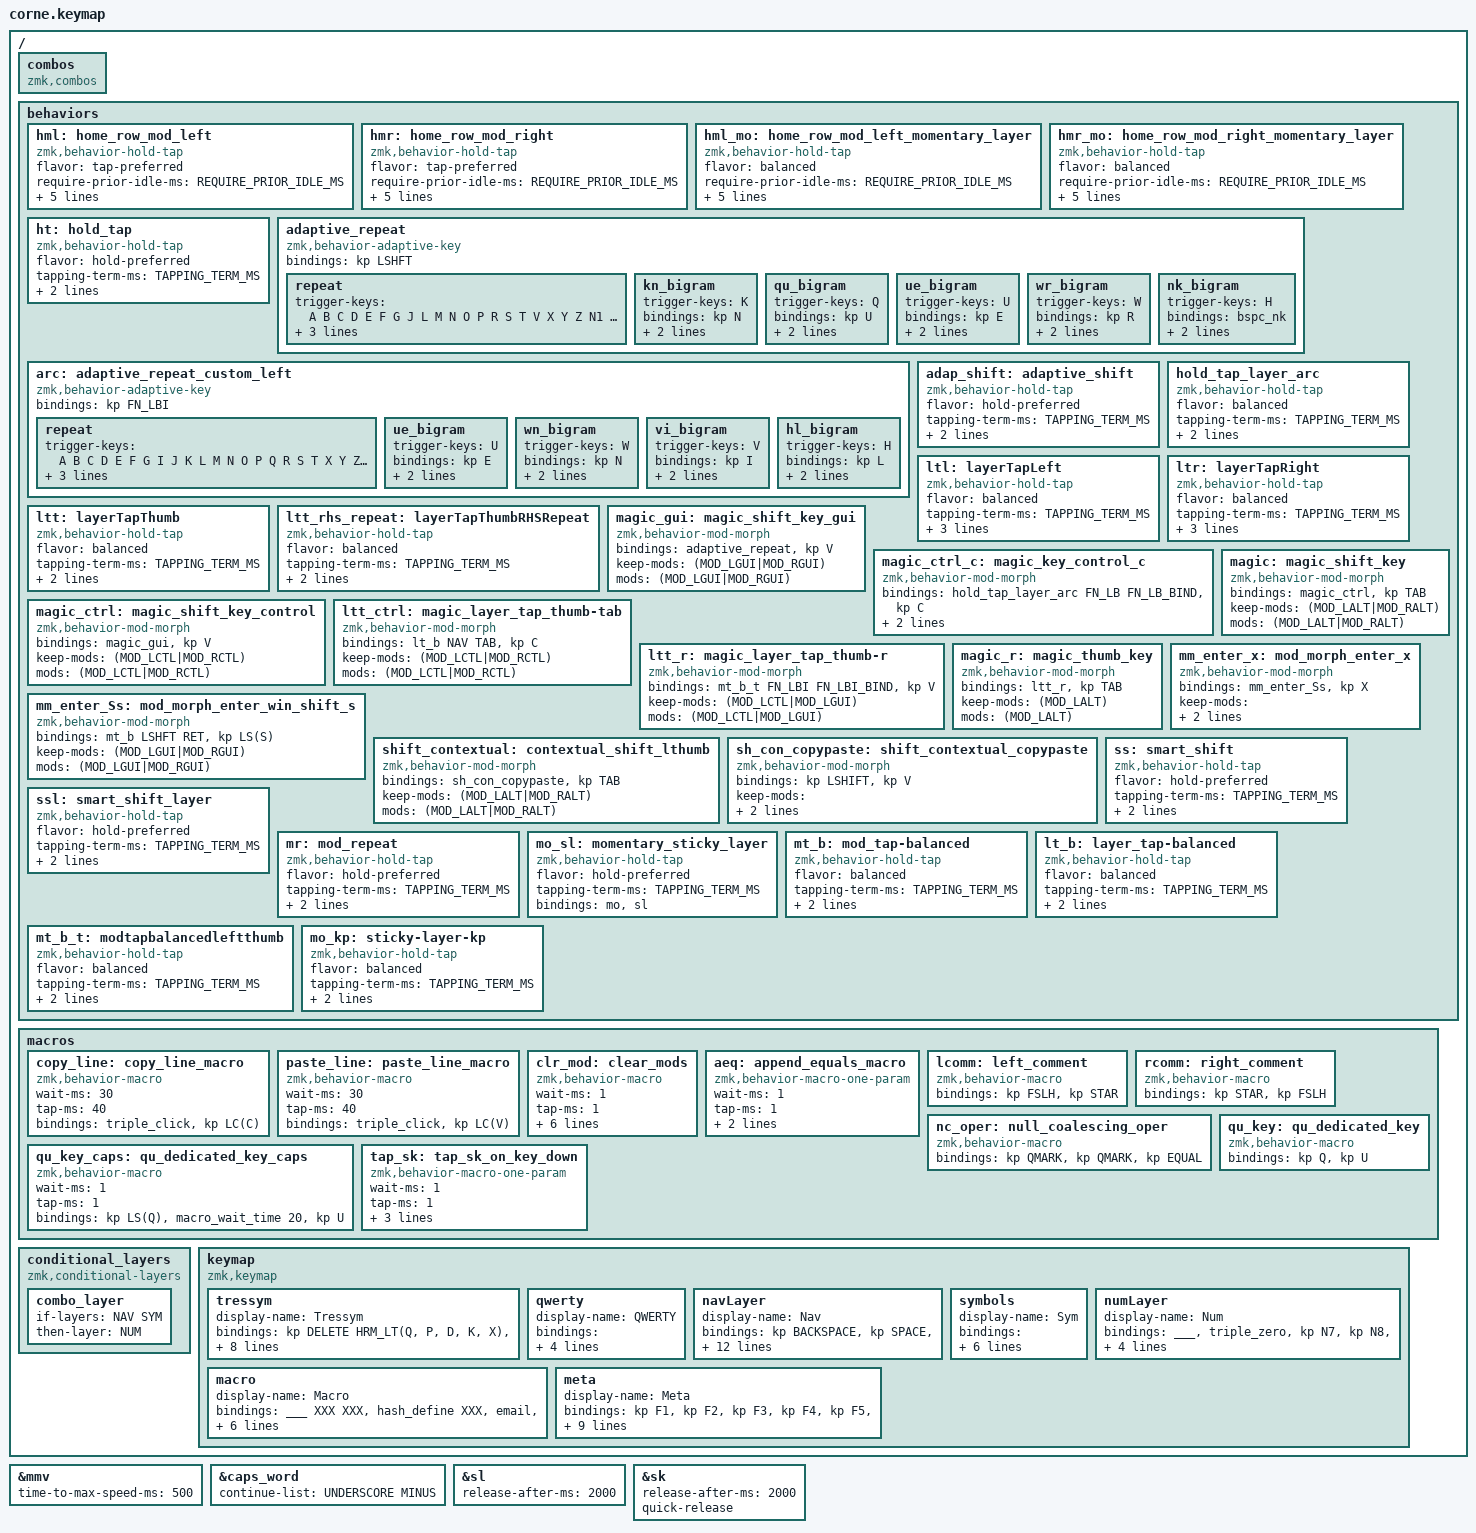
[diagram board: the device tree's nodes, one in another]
/*
 * Copyright (c) 2020 The ZMK Contributors
 *
 * SPDX-License-Identifier: MIT
 */

#include <behaviors.dtsi>
#include <dt-bindings/zmk/bt.h>

// Mouse keys
#define ZMK_POINTING_DEFAULT_MOVE_VAL 1000  // default: 600
#define ZMK_POINTING_DEFAULT_SCRL_VAL 25    // default: 10
#include <dt-bindings/zmk/pointing.h>

#define XXX &none
#define ___ &trans

// Layers
#define BASE \
0
#define QWER \
1
/*
These were in the wrong order before they were removed.
#define COLEMAK \
2
#define ENTH \
3
*/
#define NAV \
2
#define SYM \
3
#define NUM \
4
#define MACR \
5
#define META \
6


/*                                      42 KEY MATRIX / LAYOUT MAPPING

  ╭────────────────────────┬────────────────────────╮ ╭─────────────────────────┬─────────────────────────╮
  │  0   1   2   3   4   5 │  6   7   8   9  10  11 │ │ LT5 LT4 LT3 LT2 LT1 LT0 │ RT0 RT1 RT2 RT3 RT4 RT5 │
  │ 12  13  14  15  16  17 │ 18  19  20  21  22  23 │ │ LM5 LM4 LM3 LM2 LM1 LM0 │ RM0 RM1 RM2 RM3 RM4 RM5 │
  │ 24  25  26  27  28  29 │ 30  31  32  33  34  35 │ │ LB5 LB4 LB3 LB2 LB1 LB0 │ RB0 RB1 RB2 RB3 RB4 RB5 │
  ╰───────────╮ 36  37  38 │ 39  40  41 ╭───────────╯ ╰───────────╮ LH2 LH1 LH0 │ RH0 RH1 RH2 ╭───────────╯
			  ╰────────────┴────────────╯                         ╰─────────────┴─────────────╯             */

// Source key-labels.
#include <dt-bindings/zmk/keys.h>
#include "zmk-helpers/key-labels/42.h"
#define KEYS_L LT5 LT4 LT3 LT2 LT1 LT0 LM5 LM4 LM3 LM2 LM1 LM0 LB5 LB4 LB3 LB2 LB1 LB0
#define KEYS_R RT0 RT1 RT2 RT3 RT4 RT5 RM0 RM1 RM2 RM3 RM4 RM5 RB0 RB1 RB2 RB3 RB4 RB5
#define THUMBS LH2 LH1 LH0 RH0 RH1 RH2
#define THUMBS_L LH2 LH1 LH0
#define THUMBS_R RH0 RH1 RH2

// Define columns
// Left
#define LC5 LT5 LM5 LB5
#define LC4 LT4 LM4 LB4
#define LC3 LT3 LM3 LB3
#define LC2 LT2 LM2 LB2
#define LC1 LT1 LM1 LB1
#define LC0 LT0 LM0 LB0
// Right
#define RC5 RT5 RM5 RB5
#define RC4 RT4 RM4 RB4
#define RC3 RT3 RM3 RB3
#define RC2 RT2 RM2 RB2
#define RC1 RT1 RM1 RB1
#define RC0 RT0 RM0 RB0

// Define rows
// Top
#define LRT LT5 LT4 LT3 LT2 LT1 LT0
#define RRT RT0 RT1 RT2 RT3 RT4 RT5
// Middle
#define LRM LM5 LM4 LM3 LM2 LM1 LM0
#define RRM RM0 RM1 RM2 RM3 RM4 RM5
// Bottom
#define LRB LB5 LB4 LB3 LB2 LB1 LB0
#define RRB RB0 RB1 RB2 RB3 RB4 RB5


// Define HRM order

// Symbols layer is bound to middle finger because that allows you to hit }; with the current position of ; on the symbols layer.

/*
╭─────────────────────────────────────────────────┬─────────────────────────────────────────────────╮
│ HRM_LT5 HRM_LT4 HRM_LT3 HRM_LT2 HRM_LT1 HRM_LT0 │ HRM_RT0 HRM_RT1 HRM_RT2 HRM_RT3 HRM_RT4 HRM_RT5 │
│ HRM_LM5 HRM_LM4 HRM_LM3 HRM_LM2 HRM_LM1 HRM_LM0 │ HRM_RM0 HRM_RM1 HRM_RM2 HRM_RM3 HRM_RM4 HRM_RM5 │
│ HRM_LB5 HRM_LB4 HRM_LB3 HRM_LB2 HRM_LB1 HRM_LB0 │ HRM_RB0 HRM_RB1 HRM_RB2 HRM_RB3 HRM_RB4 HRM_RB5 │
╰───────────────────────╮ HRM_LH2 HRM_LH1 HRM_LH0 │ HRM_RH0 HRM_RH1 HRM_RH2 ╭───────────────────────╯
						╰─────────────────────────┴─────────────────────────╯
*/

// Top
// Left
#define HRM_LT5 XXX
#define HRM_LT4 XXX
#define HRM_LT3 XXX
#define HRM_LT2 XXX
#define HRM_LT1 XXX
#define HRM_LT0 XXX
// Right
#define HRM_RT0 XXX
#define HRM_RT1 XXX
#define HRM_RT2 XXX
#define HRM_RT3 XXX
#define HRM_RT4 XXX
#define HRM_RT5 XXX
// Middle
// Left
#define HRM_LM5 XXX
#define HRM_LM4 LGUI
#define HRM_LM3 LALT
//#define HRM_LM2 SYM
#define HRM_LM2 LSHFT
#define HRM_LM1 LCTRL
#define HRM_LM0 LSHFT
// Right
#define HRM_RM0 RSHFT
#define HRM_RM1 RCTRL
//#define HRM_RM2 SYM
#define HRM_RM2 RSHFT
#define HRM_RM3 RALT
#define HRM_RM4 RGUI
#define HRM_RM5 XXX
// Bottom
// Left
#define HRM_LB5 XXX
#define HRM_LB4 XXX
#define HRM_LB3 XXX
#define HRM_LB2 XXX
#define HRM_LB1 XXX
#define HRM_LB0 XXX
// Right
#define HRM_RB0 XXX
#define HRM_RB1 XXX
#define HRM_RB2 XXX
#define HRM_RB3 XXX
#define HRM_RB4 XXX
#define HRM_RB5 XXX


// Top row
// Left
#define HRM_LT(_one_, _two_, _three_, _four_, _five_)	\
	&kp	_one_					\
	&kp	_two_					\
	&kp _three_					\
	&kp	_four_					\
	&kp	_five_
// Right
#define HRM_RT(_one_, _two_, _three_, _four_, _five_)	\
	&kp	_one_					\
	&kp	_two_					\
	&kp _three_					\
	&kp	_four_					\
	&kp	_five_

// Middle row
// Left
#define HRM_LM(_one_, _two_, _three_, _four_, _five_)	\
	&hml	HRM_LM4 _one_		\
	&hml	HRM_LM3 _two_		\
	&hml	HRM_LM2 _three_		\
	&hml	HRM_LM1 _four_		\
	&hml	HRM_LM0 _five_
// Right
#define HRM_RM(_one_, _two_, _three_, _four_, _five_)	\
	&hmr	HRM_RM0 _one_		\
	&hmr	HRM_RM1 _two_		\
	&hmr	HRM_RM2 _three_		\
	&hmr	HRM_RM3 _four_		\
	&hmr	HRM_RM4 _five_

// Bottom row
// Left
#define HRM_LB(_one_, _two_, _three_, _four_, _five_)	\
	&kp	_one_					\
	&kp	_two_					\
	&kp _three_					\
	&kp _four_					\
	&kp	_five_
// Right
#define HRM_RB(_one_, _two_, _three_, _four_, _five_)	\
	&kp	_one_					\
	&kp _two_					\
	&kp _three_					\
	&kp	_four_					\
	&kp	_five_


// Num left | macr right : So that I can hold shift on macros.
// Positional FN defines.
//╭───────────────┬───────────────┬───────────────┬───────────────┬───────────────┬───────────────╮   ╭───────────────┬───────────────┬───────────────┬───────────────┬───────────────┬───────────────╮
//	___				___				___				___				___				___					___				___				___				___				___				___
//├───────────────┼───────────────┼───────────────┼───────────────┼───────────────┼───────────────┤   ├───────────────┼───────────────┼───────────────┼───────────────┼───────────────┼───────────────┤
	#define FN_LT MACR
																																													#define FN_RT MACR
//├───────────────┼───────────────┼───────────────┼───────────────┼───────────────┼───────────────┤   ├───────────────┼───────────────┼───────────────┼───────────────┼───────────────┼───────────────┤
//	___				___				___				___				___				___					___				___				___				___				___				___
//╰───────────────┴───────────────┴───────────────┼───────────────┼───────────────┼───────────────┤   ├───────────────┼───────────────┼───────────────┼───────────────┴───────────────┴───────────────╯
																#define FN_LB NAV
																#define FN_LB_BIND 0
																				#define FN_LBI LSHIFT
																				#define FN_LBI_BIND R
																									#define FN_RBI RSHIFT
																									#define FN_RBI_BIND SPACE
																													#define FN_RB SYM
																													#define FN_RB_BIND SQT
//                                                ╰───────────────┴───────────────┴───────────────╯   ╰───────────────┴───────────────┴───────────────╯


/*                                      42 KEY MATRIX / LAYOUT MAPPING

  ╭────────────────────────┬────────────────────────╮ ╭─────────────────────────┬─────────────────────────╮
  │  0   1   2   3   4   5 │  6   7   8   9  10  11 │ │ LT5 LT4 LT3 LT2 LT1 LT0 │ RT0 RT1 RT2 RT3 RT4 RT5 │
  │ 12  13  14  15  16  17 │ 18  19  20  21  22  23 │ │ LM5 LM4 LM3 LM2 LM1 LM0 │ RM0 RM1 RM2 RM3 RM4 RM5 │
  │ 24  25  26  27  28  29 │ 30  31  32  33  34  35 │ │ LB5 LB4 LB3 LB2 LB1 LB0 │ RB0 RB1 RB2 RB3 RB4 RB5 │
  ╰───────────╮ 36  37  38 │ 39  40  41 ╭───────────╯ ╰───────────╮ LH2 LH1 LH0 │ RH0 RH1 RH2 ╭───────────╯
			  ╰────────────┴────────────╯                         ╰─────────────┴─────────────╯             */

// Combos
/ {
	combos {
		compatible = "zmk,combos";
		// Q macro, Q is Qu instead.
		//combo_q { timeout-ms = <50>; key-positions = <LT4 LT3>; bindings = <&kp Q>; };
		// Bootloader access.
		//combo_rst_l { timeout-ms = <50>; key-positions = <LT0 LM5 LH1>; bindings = <&bootloader>; };
		//combo_rst_r { timeout-ms = <50>; key-positions = <RT0 RM5 RH1>; bindings = <&bootloader>; };

		// ( / )
		//combo_l_paren { timeout-ms = <50>; key-positions = <LT3 LT2 LM1>; bindings = <&kp LS(N9)>; };
		//combo_r_paren { timeout-ms = <50>; key-positions = <LM3 LT2 LT1>; bindings = <&kp LS(N0)>; };
		// { / }
		//combo_l_brace { timeout-ms = <50>; key-positions = <RT1 RT2 RM3>; bindings = <&kp LBRC>; };
		//combo_r_brace { timeout-ms = <50>; key-positions = <RM1 RT2 RT3>; bindings = <&kp RBRC>; };
		// [ / ]
		//combo_l_bracket { timeout-ms = <50>; key-positions = <LB3 LB2 >; bindings = <&kp LBKT>; };
		//combo_r_bracket { timeout-ms = <50>; key-positions = <LB2 LB1>; bindings = <&kp RBKT>; };
		// < / >
		//combo_l_abk { timeout-ms = <50>; key-positions = <RB2 RB1>; bindings = <&kp LT>; };
		//combo_r_abk { timeout-ms = <50>; key-positions = <RB3 RB2>; bindings = <&kp GT>; };
		// Both thumbs produces shift.
		//combo_shift_thumbs { timeout-ms = <50>; key-positions = <LH0 RH0>; bindings = <&kp LSHFT>; };
	};
};


/* Homerow mods */
#include "zmk-helpers/helper.h"

#define QUICK_TAP_MS 150
#define TAPPING_TERM_MS 160

// Generic <unshifted>, <shifted>
#define MOD_MORPH_GENERIC(_name_, _unshifted_, _shifted_)	\
_name_: _name_##mod_morph_generic_shift {					\
	compatible = "zmk,behavior-mod-morph";					\
	#binding-cells = <0>;									\
	bindings = <_unshifted_>, <_shifted_>;					\
	mods = <(MOD_LSFT|MOD_RSFT)>;							\
};
// Generic HML macros
#define HML_GENERIC(_name_, _binding_)						\
hml_##_name_: home_row_mod_left_##_name_ {					\
	compatible = "zmk,behavior-hold-tap";					\
	#binding-cells = <2>;									\
	flavor = "balanced";									\
	require-prior-idle-ms = <150>;							\
	tapping-term-ms = <TAPPING_TERM_MS>;					\
	quick-tap-ms = <QUICK_TAP_MS>;							\
	bindings = <&kp>, <_binding_>;							\
	hold-trigger-key-positions = <KEYS_R THUMBS>; /* RHS */	\
	hold-trigger-on-release;								\
};
#define HMR_GENERIC(_name_, _binding_)	\
hmr_##_name_: home_row_mod_right_##_name_ {					\
	compatible = "zmk,behavior-hold-tap";					\
	#binding-cells = <2>;									\
	flavor = "balanced";									\
	require-prior-idle-ms = <150>;							\
	tapping-term-ms = <TAPPING_TERM_MS>;					\
	quick-tap-ms = <QUICK_TAP_MS>;							\
	bindings = <&kp>, <_binding_>;							\
	hold-trigger-key-positions = <KEYS_L THUMBS>; /* LHS */	\
	hold-trigger-on-release;								\
};


// ARC Idle ms
#define MAX_PRIOR_IDLE_MS 350
#define ARC_MAX_PRIOR_IDLE_MS 1000

// HRM Idle ms
#define REQUIRE_PRIOR_IDLE_MS 200

// Non-macro setup
/ {
	behaviors {
		// Home row mods
		hml: home_row_mod_left {
			compatible = "zmk,behavior-hold-tap";
			#binding-cells = <2>;
			flavor = "tap-preferred";
			require-prior-idle-ms = <REQUIRE_PRIOR_IDLE_MS>;
			tapping-term-ms = <TAPPING_TERM_MS>;
			quick-tap-ms = <QUICK_TAP_MS>;
			bindings = <&kp>, <&kp>;
			// List of keys on the right side of the keyboard
			hold-trigger-key-positions = <KEYS_R THUMBS>;
			hold-trigger-on-release;
		};
		hmr: home_row_mod_right {
			compatible = "zmk,behavior-hold-tap";
			#binding-cells = <2>;
			flavor = "tap-preferred";
			require-prior-idle-ms = <REQUIRE_PRIOR_IDLE_MS>;
			tapping-term-ms = <TAPPING_TERM_MS>;
			quick-tap-ms = <QUICK_TAP_MS>;
			bindings = <&kp>, <&kp>;
			// List of keys on the left side of the keyboard
			hold-trigger-key-positions = <KEYS_L THUMBS>;
			hold-trigger-on-release;
		};
		// Home row momentary layer keys
		hml_mo: home_row_mod_left_momentary_layer {
			compatible = "zmk,behavior-hold-tap";
			#binding-cells = <2>;
			flavor = "balanced";
			require-prior-idle-ms = <REQUIRE_PRIOR_IDLE_MS>;
			tapping-term-ms = <TAPPING_TERM_MS>;
			quick-tap-ms = <QUICK_TAP_MS>;
			bindings = <&mo>, <&kp>;
			// List of keys on the right side of the keyboard
			hold-trigger-key-positions = <KEYS_R THUMBS>;
			hold-trigger-on-release;
		};
		hmr_mo: home_row_mod_right_momentary_layer {
			compatible = "zmk,behavior-hold-tap";
			#binding-cells = <2>;
			flavor = "balanced";
			require-prior-idle-ms = <REQUIRE_PRIOR_IDLE_MS>;
			tapping-term-ms = <TAPPING_TERM_MS>;
			quick-tap-ms = <QUICK_TAP_MS>;
			bindings = <&mo>, <&kp>;
			// List of keys on the left side of the keyboard
			hold-trigger-key-positions = <KEYS_L THUMBS>;
			hold-trigger-on-release;
		};

		// Hold tap
		ht: hold_tap {
			compatible = "zmk,behavior-hold-tap";
			#binding-cells = <2>;
			flavor = "hold-preferred";
			//require-prior-idle-ms = <150>;
			tapping-term-ms = <TAPPING_TERM_MS>;
			quick-tap-ms = <QUICK_TAP_MS>;
			bindings = <&kp>, <&kp>;
			// List of keys on the left side of the keyboard
			//hold-trigger-key-positions = <RC5 KEYS_L THUMBS>;
			//hold-trigger-on-release;
		};

		// Magic shift / adaptive key
		adaptive_repeat: adaptive_repeat {
			compatible = "zmk,behavior-adaptive-key";
			#binding-cells = <0>;
			//bindings = <&adap_shift LSHFT TAB>;
			//bindings = <___>;
			bindings = <&kp LSHFT>;
			repeat {
				trigger-keys = <
					A B C D E F G J L M N O P R S T V X Y Z
					N1 N2 N3 N4 N5 N6 N7 N8 N9 N0
					TAB
					EXCL MINUS BSLH AT HASH PRCNT PLUS EQUAL GRAVE
					LT LBKT LBRC RS(N9) SPACE DOLLAR LS(N0) RBRC RBKT GT
					DQT COMMA TILDE CARET FSLH SEMI COLON STAR PIPE AMPS DOT SQT
				>;
				bindings = <&key_repeat>;
				max-prior-idle-ms = <MAX_PRIOR_IDLE_MS>;
				strict-modifiers;
			};
			// Single finger bigram prevention.
			kn_bigram {
				trigger-keys = <K>;
				bindings = <&kp N>;
				max-prior-idle-ms = <MAX_PRIOR_IDLE_MS>;
				strict-modifiers;
			};
			/* This one was too annoying.
			nk_bigram {
				trigger-keys = <N>;
				bindings = <&kp K>;
				max-prior-idle-ms = <MAX_PRIOR_IDLE_MS>;
				strict-modifiers;
			};
			*/
			qu_bigram {
				trigger-keys = <Q>;
				bindings = <&kp U>;
				max-prior-idle-ms = <MAX_PRIOR_IDLE_MS>;
				strict-modifiers;
			};
			ue_bigram {
				trigger-keys = <U>;
				bindings = <&kp E>;
				max-prior-idle-ms = <MAX_PRIOR_IDLE_MS>;
				strict-modifiers;
			};
			wr_bigram {
				trigger-keys = <W>;
				bindings = <&kp R>;
				max-prior-idle-ms = <MAX_PRIOR_IDLE_MS>;
				strict-modifiers;
			};
			// i?_bigram
			// The I bigram is disabled due to the frequency with which I use the key in VIM to start typing.
			// NK Bigram
			nk_bigram {
				trigger-keys = <H>;
				bindings = <&bspc_nk>;
				max-prior-idle-ms = <MAX_PRIOR_IDLE_MS>;
				strict-modifiers;
			};
		};

		// Magic shift / adaptive key
		arc: adaptive_repeat_custom_left {
			compatible = "zmk,behavior-adaptive-key";
			#binding-cells = <0>;
			//bindings = <&adap_shift LSHFT TAB>;
			bindings = <&kp FN_LBI>;
			repeat {
				trigger-keys = <
					A B C D E F G I J K L M N O P Q R S T X Y Z
					N1 N2 N3 N4 N5 N6 N7 N8 N9 N0
					TAB
					EXCL MINUS BSLH AT HASH PRCNT PLUS EQUAL GRAVE
					LT LBKT LBRC RS(N9) SPACE DOLLAR LS(N0) RBRC RBKT GT
					DQT COMMA TILDE CARET FSLH SEMI COLON STAR PIPE AMPS DOT SQT
				>;
				bindings = <&key_repeat>;
				max-prior-idle-ms = <ARC_MAX_PRIOR_IDLE_MS>;
				strict-modifiers;
			};
			// Single finger bigram prevention.
			ue_bigram {
				trigger-keys = <U>;
				bindings = <&kp E>;
				max-prior-idle-ms = <ARC_MAX_PRIOR_IDLE_MS>;
				strict-modifiers;
			};
			wn_bigram {
				trigger-keys = <W>;
				bindings = <&kp N>;
				max-prior-idle-ms = <ARC_MAX_PRIOR_IDLE_MS>;
				strict-modifiers;
			};
			vi_bigram {
				trigger-keys = <V>;
				bindings = <&kp I>;
				max-prior-idle-ms = <ARC_MAX_PRIOR_IDLE_MS>;
				strict-modifiers;
			};
			hl_bigram {
				trigger-keys = <H>;
				bindings = <&kp L>;
				max-prior-idle-ms = <ARC_MAX_PRIOR_IDLE_MS>;
				strict-modifiers;
			};
		};

		adap_shift: adaptive_shift {
			compatible = "zmk,behavior-hold-tap";
			#binding-cells = <2>;
			flavor = "hold-preferred";
			//require-prior-idle-ms = <150>;
			tapping-term-ms = <TAPPING_TERM_MS>;
			quick-tap-ms = <QUICK_TAP_MS>;
			bindings = <&kp>, <&kp>;
			//hold-trigger-key-positions = <RC5 KEYS_L THUMBS>; // List of keys on the left side of the keyboard
			//hold-trigger-on-release;
		};

		hold_tap_layer_arc: hold_tap_layer_arc {
			compatible = "zmk,behavior-hold-tap";
			#binding-cells = <2>;
			flavor = "balanced";
			tapping-term-ms = <TAPPING_TERM_MS>;
			quick-tap-ms = <QUICK_TAP_MS>;
			bindings = <&mo>, <&arc>;
		};

		// Left hand layer tap key
		ltl: layerTapLeft {
			compatible = "zmk,behavior-hold-tap";
			#binding-cells = <2>;
			flavor = "balanced";
			//require-prior-idle-ms = <150>;
			tapping-term-ms = <TAPPING_TERM_MS>;
			quick-tap-ms = <QUICK_TAP_MS>;
			bindings = <&mo>, <&kp>;
			hold-trigger-key-positions = <LC5 KEYS_R THUMBS>; /* RHS */
			//hold-trigger-on-release;
		};

		// Right hand layer tap key
		ltr: layerTapRight {
			compatible = "zmk,behavior-hold-tap";
			#binding-cells = <2>;
			flavor = "balanced";
			//require-prior-idle-ms = <150>;
			tapping-term-ms = <TAPPING_TERM_MS>;
			quick-tap-ms = <QUICK_TAP_MS>;
			bindings = <&mo>, <&kp>;
			hold-trigger-key-positions = <RC5 KEYS_L THUMBS>; /* LHS */
			//hold-trigger-on-release;
		};

		// Right hand layer tap key
		ltt: layerTapThumb {
			compatible = "zmk,behavior-hold-tap";
			#binding-cells = <2>;
			flavor = "balanced";
			//require-prior-idle-ms = <150>;
			tapping-term-ms = <TAPPING_TERM_MS>;
			quick-tap-ms = <QUICK_TAP_MS>;
			bindings = <&mo>, <&kp>;
			//hold-trigger-key-positions = <RC5 KEYS_L THUMBS>; /* LHS */
			//hold-trigger-on-release;
		};
		ltt_rhs_repeat: layerTapThumbRHSRepeat {
			compatible = "zmk,behavior-hold-tap";
			#binding-cells = <2>;
			flavor = "balanced";
			//require-prior-idle-ms = <150>;
			tapping-term-ms = <TAPPING_TERM_MS>;
			quick-tap-ms = <QUICK_TAP_MS>;
			bindings = <&kp>, <&adaptive_repeat>;
			//hold-trigger-key-positions = <RC5 KEYS_L THUMBS>; /* LHS */
			//hold-trigger-on-release;
		};

		/*
		HML_GENERIC(dot_cln, &dot_cln)
		HML_GENERIC(EN4, &EN4)
		HML_GENERIC(EN5, &EN5)
		HML_GENERIC(EN6, &EN6)
		*/


		// Mod morphs
		magic_gui: magic_shift_key_gui {
			compatible = "zmk,behavior-mod-morph";
			#binding-cells = <0>;
			bindings = <&adaptive_repeat>, <&kp V>;
			keep-mods = <(MOD_LGUI|MOD_RGUI)>;
			mods = <(MOD_LGUI|MOD_RGUI)>;
		};
		magic_ctrl_c: magic_key_control_c {
			compatible = "zmk,behavior-mod-morph";
			#binding-cells = <0>;
			//bindings = <&mt_b FN_LB FN_LB_BIND>, <&kp C>;
			bindings = <&hold_tap_layer_arc FN_LB FN_LB_BIND>, <&kp C>;
			keep-mods = <(MOD_LCTL|MOD_RCTL)>;
			mods = <(MOD_LCTL|MOD_RCTL)>;
		};
		magic_ctrl: magic_shift_key_control {
			compatible = "zmk,behavior-mod-morph";
			#binding-cells = <0>;
			bindings = <&magic_gui>, <&kp V>;
			keep-mods = <(MOD_LCTL|MOD_RCTL)>;
			mods = <(MOD_LCTL|MOD_RCTL)>;
		};
		magic: magic_shift_key {
			compatible = "zmk,behavior-mod-morph";
			#binding-cells = <0>;
			bindings = <&magic_ctrl>, <&kp TAB>;
			keep-mods = <(MOD_LALT|MOD_RALT)>;
			mods = <(MOD_LALT|MOD_RALT)>;
		};
		ltt_ctrl: magic_layer_tap_thumb-tab {
			compatible = "zmk,behavior-mod-morph";
			#binding-cells = <0>;
			//bindings = <&ltt FN_LB MINUS>, <&kp C>;
			// Hardcoded to avoid conflict with other layers.
			bindings = <&lt_b NAV TAB>, <&kp C>;
			keep-mods = <(MOD_LCTL|MOD_RCTL)>;
			mods = <(MOD_LCTL|MOD_RCTL)>;
		};
		ltt_r: magic_layer_tap_thumb-r {
			compatible = "zmk,behavior-mod-morph";
			#binding-cells = <0>;
			//bindings = <&ltt FN_LB MINUS>, <&kp C>;
			bindings = <&mt_b_t FN_LBI FN_LBI_BIND>, <&kp V>;
			//keep-mods = <(MOD_LCTL|MOD_RCTL|MOD_LGUI|MOD_RGUI)>;
			keep-mods = <(MOD_LCTL|MOD_LGUI)>;
			//mods = <(MOD_LCTL|MOD_RCTL|MOD_LGUI|MOD_RGUI)>;
			mods = <(MOD_LCTL|MOD_LGUI)>;
		};
		magic_r: magic_thumb_key {
			compatible = "zmk,behavior-mod-morph";
			#binding-cells = <0>;
			//bindings = <&ltt FN_LB MINUS>, <&kp C>;
			bindings = <&ltt_r>, <&kp TAB>;
			//keep-mods = <(MOD_LALT|MOD_RALT)>;
			keep-mods = <(MOD_LALT)>;
			//mods = <(MOD_LALT|MOD_RALT)>;
			mods = <(MOD_LALT)>;
		};
		mm_enter_x: mod_morph_enter_x {
			compatible = "zmk,behavior-mod-morph";
			#binding-cells = <0>;
			bindings = <&mm_enter_Ss>, <&kp X>;
			keep-mods = <(MOD_LCTL|MOD_RCTL|MOD_LGUI|MOD_RGUI)>;
			mods = <(MOD_LCTL|MOD_RCTL)>;
		};
		mm_enter_Ss: mod_morph_enter_win_shift_s {
			compatible = "zmk,behavior-mod-morph";
			#binding-cells = <0>;
			bindings = <&mt_b LSHFT RET>, <&kp LS(S)>;
			keep-mods = <(MOD_LGUI|MOD_RGUI)>;
			mods = <(MOD_LGUI|MOD_RGUI)>;
		};

		shift_contextual: contextual_shift_lthumb {
			compatible = "zmk,behavior-mod-morph";
			#binding-cells = <0>;
			bindings = <&sh_con_copypaste>, <&kp TAB>;
			keep-mods = <(MOD_LALT|MOD_RALT)>;
			mods = <(MOD_LALT|MOD_RALT)>;
		};
		sh_con_copypaste: shift_contextual_copypaste {
			compatible = "zmk,behavior-mod-morph";
			#binding-cells = <0>;
			//bindings = <&ltt FN_LB MINUS>, <&kp C>;
			bindings = <&kp LSHIFT>, <&kp V>;
			keep-mods = <(MOD_LCTL|MOD_RCTL|MOD_LGUI|MOD_RGUI)>;
			mods = <(MOD_LCTL|MOD_RCTL|MOD_LGUI|MOD_RGUI)>;
		};

		// , / ;
		MOD_MORPH_GENERIC(c_scln, &kp COMMA, &kp SEMI)
		// . / :
		MOD_MORPH_GENERIC(dot_cln, &kp DOT, &kp COLON)
		// ! / ?
		MOD_MORPH_GENERIC(bqm, &kp EXCL, &kp QMARK)
		// ? / !
		MOD_MORPH_GENERIC(qmb, &kp QMARK, &kp EXCL)
		// Space / Underscore
		MOD_MORPH_GENERIC(spund, &kp SPACE, &kp UNDER)
		// Underscore / Minus
		MOD_MORPH_GENERIC(undmin, &kp UNDER, &kp MINUS)
		// Forwardslash / Backslash
		MOD_MORPH_GENERIC(fsbs, &kp FSLH, &kp BACKSLASH)
		// qu / Qu
		MOD_MORPH_GENERIC(QU_bi, &qu_key, &qu_key_caps)

		// Explicit digit keycodes, so they can't be shifted into symbols.
		MOD_MORPH_GENERIC(EN1, &kp N1, &kp N1)
		MOD_MORPH_GENERIC(EN2, &kp N2, &kp N2)
		MOD_MORPH_GENERIC(EN3, &kp N3, &kp N3)
		MOD_MORPH_GENERIC(EN4, &kp N4, &kp N4)
		MOD_MORPH_GENERIC(EN5, &kp N5, &kp N5)
		MOD_MORPH_GENERIC(EN6, &kp N6, &kp N6)
		MOD_MORPH_GENERIC(EN7, &kp N7, &kp N7)
		MOD_MORPH_GENERIC(EN8, &kp N8, &kp N8)
		MOD_MORPH_GENERIC(EN9, &kp N9, &kp N9)
		MOD_MORPH_GENERIC(EN0, &kp N0, &kp N0)

		// Bluetooth clear hold
		//MOD_MORPH_GENERIC(btc_hold, XXX, &bt BT_CLR)

		// Numbers / F keys row
		MOD_MORPH_GENERIC(mm_transF1, &trans, &kp F1)
		//MOD_MORPH_GENERIC(mm_transF1, &kp TAB, &kp F1)
		MOD_MORPH_GENERIC(mm_N1F2,	&kp N1, &kp F2)
		MOD_MORPH_GENERIC(mm_N2F3,	&kp N2, &kp F3)
		MOD_MORPH_GENERIC(mm_N3F4,	&kp N3, &kp F4)
		MOD_MORPH_GENERIC(mm_N4F5,	&kp N4, &kp F5)
		MOD_MORPH_GENERIC(mm_N5F6,	&kp N5, &kp F6)
		MOD_MORPH_GENERIC(mm_N6F7,	&kp N6, &kp F7)
		MOD_MORPH_GENERIC(mm_N7F8,	&kp N7, &kp F8)
		MOD_MORPH_GENERIC(mm_N8F9,	&kp N8, &kp F9)
		MOD_MORPH_GENERIC(mm_N9F10,	&kp N9, &kp F10)
		MOD_MORPH_GENERIC(mm_N0F11,	&kp N0, &kp F11)
		MOD_MORPH_GENERIC(mm_transF12, &trans, &kp F12)
		//MOD_MORPH_GENERIC(mm_transF12, &kp BSPC, &kp F12)

		MOD_MORPH_GENERIC(mm_bt0, &bt BT_SEL 0, &bt BT_DISC 0)
		MOD_MORPH_GENERIC(mm_bt1, &bt BT_SEL 1, &bt BT_DISC 1)
		MOD_MORPH_GENERIC(mm_bt2, &bt BT_SEL 2, &bt BT_DISC 2)
		MOD_MORPH_GENERIC(mm_bt3, &bt BT_SEL 3, &bt BT_DISC 3)
		MOD_MORPH_GENERIC(mm_bt4, &bt BT_SEL 4, &bt BT_DISC 4)

		// Mod morph for nullptr / NULL macros
		MOD_MORPH_GENERIC(np, &null_pointer, &null_capitals)

		// Hold tap for smart_shift
		ss: smart_shift {
			compatible = "zmk,behavior-hold-tap";
			#binding-cells = <2>;
			flavor = "hold-preferred";
			tapping-term-ms = <TAPPING_TERM_MS>;
			bindings = <&kp>, <&caps_word>;
			display-name = "smartShift";
		};
		// Layer tap for smart_shift
		ssl: smart_shift_layer {
			compatible = "zmk,behavior-hold-tap";
			#binding-cells = <2>;
			flavor = "hold-preferred";
			tapping-term-ms = <TAPPING_TERM_MS>;
			bindings = <&mo>, <&kt>;
			display-name = "smartShift";
		};
		// Shift / Repeat
		mr: mod_repeat {
			compatible = "zmk,behavior-hold-tap";
			#binding-cells = <2>;
			flavor = "hold-preferred";
			tapping-term-ms = <TAPPING_TERM_MS>;
			bindings = <&kp>, <&key_repeat>;
			display-name = "modRepeat";
		};

		// Momentary / sticky layer
		mo_sl: momentary_sticky_layer {
			compatible = "zmk,behavior-hold-tap";
			#binding-cells = <2>;
			flavor = "hold-preferred";
			tapping-term-ms = <TAPPING_TERM_MS>;
			bindings = <&mo>, <&sl>;
		};

		mt_b: mod_tap-balanced {
			compatible = "zmk,behavior-hold-tap";
			#binding-cells = <2>;
			flavor = "balanced";
			tapping-term-ms = <TAPPING_TERM_MS>;
			bindings = <&kp>, <&kp>;
			display-name = "Mod_Tap-balanced";
		};
		lt_b: layer_tap-balanced {
			compatible = "zmk,behavior-hold-tap";
			#binding-cells = <2>;
			flavor = "balanced";
			tapping-term-ms = <TAPPING_TERM_MS>;
			bindings = <&mo>, <&kp>;
			display-name = "Layer_Tap-balanced";
		};

		mt_b_t: modtapbalancedleftthumb {
			compatible = "zmk,behavior-hold-tap";
			#binding-cells = <2>;
			flavor = "balanced";
			tapping-term-ms = <TAPPING_TERM_MS>;
			bindings = <&kp>, <&kp>;
			display-name = "Mod_Tap-balanced";
		};

		mo_kp: sticky-layer-kp {
			compatible = "zmk,behavior-hold-tap";
			#binding-cells = <2>;
			flavor = "balanced";
			tapping-term-ms = <TAPPING_TERM_MS>;
			bindings = <&mo>, <&kp>;
			display-name = "Layer_Tap-balanced";
		};
	};
};


// Macros
#define MACRO(_name_, _bindings_)			\
_name_: macro_##_name_ {					\
	compatible		= "zmk,behavior-macro";	\
	#binding-cells	= <0>;					\
	tap-ms			= <1>;					\
	wait-ms			= <1>;					\
	bindings		= <_bindings_>;			\
};

/ {
	macros {
		// <-
		MACRO(larr, &kp LT &kp MINUS)
		// <=
		MACRO(learr, &kp LT &kp EQUAL)
		// ->
		MACRO(rarr, &kp MINUS &kp GT)
		// =>
		MACRO(rearr, &kp EQUAL &kp GT)
		// True
		MACRO(m_true, &kp T &kp R &kp U &kp E)
		// False
		MACRO(m_false, &kp F &kp A &kp L &kp S &kp E)
		// nullptr
		MACRO(null_pointer, &kp N &kp U &kp L &kp L &kp P &kp T &kp R)
		// NULL
		MACRO(null_capitals, &kp LS(N) &kp LS(U) &kp LS(L) &kp LS(L))
		// #include
		MACRO(hash_include, &kp HASH &kp I &kp N &kp C &kp L &kp U &kp D &kp E)
		// #define
		MACRO(hash_define, &kp HASH &kp D &kp E &kp F &kp I &kp N &kp E)
		// Shebang : #!/
		MACRO(shebang, &kp HASH &kp EXCL &kp SLASH)
		// Print email address
		MACRO(email, &kp J &kp A &kp G &kp E &kp R &kp DOT &kp M &kp H &kp AT &kp G &kp M &kp A &kp I &kp L &kp DOT &kp C &kp O &kp M)
		// sizeof
		MACRO(sizeof_kw, &kp S &kp I &kp Z &kp E &kp O &kp F)
		// const
		MACRO(const_kw, &kp C &kp O &kp N &kp S &kp T)
		// 00
		MACRO(double_zero, &kp N0 &kp N0)
		// 000
		MACRO(triple_zero, &kp N0 &kp N0 &kp N0)
		// 128
		MACRO(b128, &kp N1 &kp N2 &kp N8)
		// 64
		MACRO(b64, &kp N6 &kp N4)
		// 32
		MACRO(b32, &kp N3 &kp N2)
		// 16
		MACRO(b16, &kp N1 &kp N6)
		// Triple click
		MACRO(triple_click, &mkp LCLK &mkp LCLK &mkp LCLK)
		// Copy line
		//MACRO(copy_line, &triple_click &kp LC(C))
		// Backspace then N K bigram macro
		MACRO(bspc_nk, &kp BACKSPACE &kp N &kp K)

		copy_line: copy_line_macro {
			compatible		= "zmk,behavior-macro";
			#binding-cells	= <0>;
			wait-ms = <30>;
			tap-ms = <40>;
			bindings =
				//<&macro_release &kp LSHFT>,
				//<&macro_release &kp RSHFT>,
				<&triple_click>,
				<&kp LC(C)>;
		};

		paste_line: paste_line_macro {
			compatible		= "zmk,behavior-macro";
			#binding-cells	= <0>;
			wait-ms = <30>;
			tap-ms = <40>;
			bindings =
				//<&macro_release &kp LSHFT>,
				//<&macro_release &kp RSHFT>,
				<&triple_click>,
				<&kp LC(V)>;
		};

		clr_mod: clear_mods {
			compatible = "zmk,behavior-macro";
			#binding-cells = <0>;
			wait-ms = <1>;
			tap-ms = <1>;
			bindings =	<&macro_release &kp LSHFT>,
						<&macro_release &kp RSHFT>,
						<&macro_release &kp LCTRL>,
						<&macro_release &kp RCTRL>,
						<&macro_release &kp LALT>,
						<&macro_release &kp RALT>,
						<&macro_release &kp LGUI>,
						<&macro_release &kp RGUI>;
		};
		// Append =
		aeq: append_equals_macro {
			compatible = "zmk,behavior-macro-one-param";
			#binding-cells = <1>; // Must be 1
			wait-ms = <1>;
			tap-ms = <1>;
			bindings = <&macro_param_1to1>, <&kp MACRO_PLACEHOLDER>, <&kp EQUAL>;
		};
		// c style comments
		// /*
		lcomm: left_comment {
			compatible = "zmk,behavior-macro";
			#binding-cells = <0>;
			bindings = <&kp FSLH &kp STAR>;
		};
		// */
		rcomm: right_comment {
			compatible = "zmk,behavior-macro";
			#binding-cells = <0>;
			bindings = <&kp STAR &kp FSLH>;
		};
		// ??=
		nc_oper: null_coalescing_oper {
			compatible = "zmk,behavior-macro";
			#binding-cells = <0>;
			bindings = <&kp QMARK &kp QMARK &kp EQUAL>;
		};
		qu_key: qu_dedicated_key {
			compatible = "zmk,behavior-macro";
			#binding-cells = <0>;
			bindings = <&kp Q &kp U>;
		};
		qu_key_caps: qu_dedicated_key_caps {
			compatible = "zmk,behavior-macro";
			#binding-cells = <0>;
			wait-ms = <1>;
			tap-ms = <1>;
			bindings = <&kp LS(Q)>
					//, <&macro_release &kp LSHFT>
					//, <&macro_release &kp RSHFT>
					 , <&macro_wait_time 20>
					 , <&kp U>;
		};
		tap_sk: tap_sk_on_key_down {
			compatible = "zmk,behavior-macro-one-param";
			#binding-cells = <1>;
			wait-ms = <1>;
			tap-ms = <1>;
			bindings =	<&macro_param_1to1>,
						<&sk MACRO_PLACEHOLDER>,
						<&macro_pause_for_release>;
		};
	};
};

&mmv {
    //x-input-code = <INPUT_REL_X>;
    //y-input-code = <INPUT_REL_Y>;
    time-to-max-speed-ms = <500>;
    //acceleration-exponent = <1>;
};

// Caps word
&caps_word {
	continue-list = <UNDERSCORE MINUS>;
};

&sl {
	release-after-ms = <2000>;
};

&sk {
	release-after-ms = <2000>;
	quick-release;
};

/ {
	conditional_layers {
		compatible = "zmk,conditional-layers";
		combo_layer {
			if-layers = <NAV SYM>;
			then-layer = <NUM>;
		};
	};
};


/ {
	keymap {
		compatible = "zmk,keymap";

		tressym {
			display-name = "Tressym";
			bindings = <
//╭───────────────┬───────────────┬───────────────┬───────────────┬───────────────┬───────────────╮   ╭───────────────┬───────────────┬───────────────┬───────────────┬───────────────┬───────────────╮
	&kp DELETE		HRM_LT(Q,		P,				D,				K,				X)					&fsbs			&kp TAB			&kp A			&c_scln			&kp Z			&kp BACKSPACE
//├───────────────┼───────────────┼───────────────┼───────────────┼───────────────┼───────────────┤   ├───────────────┼───────────────┼───────────────┼───────────────┼───────────────┼───────────────┤
	&kp W			HRM_LM(C,		N,				T,				H,				M)					HRM_RM(MINUS,	E,				O,				I,				S)				&kp V
//├───────────────┼───────────────┼───────────────┼───────────────┼───────────────┼───────────────┤   ├───────────────┼───────────────┼───────────────┼───────────────┼───────────────┼───────────────┤
	&ssl FN_LT LSHFT HRM_LB(Y,		B,				G,				L,				J)					&kp UNDER		&kp U			&qmb			&dot_cln		&kp F			&mo_kp FN_RT CAPS
//╰───────────────┴───────────────┴───────────────┼───────────────┼───────────────┼───────────────┤   ├───────────────┼───────────────┼───────────────┼───────────────┴───────────────┴───────────────╯
													&mm_enter_x		&magic_ctrl_c	&magic_r	&mt_b_t FN_RBI FN_RBI_BIND &lt_b FN_RB FN_RB_BIND &mt_b RSHIFT ESC
//                                                ╰───────────────┴───────────────┴───────────────╯   ╰───────────────┴───────────────┴───────────────╯
			>;
		};


/*
		colemak-dh {
			display-name = "Colemak";
			bindings = <
//╭───────────────┬───────────────┬───────────────┬───────────────┬───────────────┬───────────────╮   ╭───────────────┬───────────────┬───────────────┬───────────────┬───────────────┬───────────────╮
	&kp DELETE		HRM_LT(Q,		W,				F,				P,				B)					&kp J			&kp L			&kp U			&kp Y			&qmb			&kp BACKSPACE
//├───────────────┼───────────────┼───────────────┼───────────────┼───────────────┼───────────────┤   ├───────────────┼───────────────┼───────────────┼───────────────┼───────────────┼───────────────┤
	&kp Q			HRM_LM(A,		R,				S,				T,				G)					HRM_RM(M,		N,				E,				I,				O)				&qmb
//├───────────────┼───────────────┼───────────────┼───────────────┼───────────────┼───────────────┤   ├───────────────┼───────────────┼───────────────┼───────────────┼───────────────┼───────────────┤
	&ssl MACR 0		HRM_LB(Z,		X,				C,				D,				V)					&kp K			&kp H			&c_scln			&dot_cln		&kp SQT			&lt FN_RT CAPS
//╰───────────────┴───────────────┴───────────────┼───────────────┼───────────────┼───────────────┤   ├───────────────┼───────────────┼───────────────┼───────────────┴───────────────┴───────────────╯
													&mm_enter_x		&ltt_ctrl		&magic			&mt_b RSHFT SPACE &lt_b SYM MINUS &mt_b RSHFT ESC
//                                                ╰───────────────┴───────────────┴───────────────╯   ╰───────────────┴───────────────┴───────────────╯
			>;
		};
*/


		qwerty {
			display-name = "QWERTY";
			bindings = <
//╭───────────────┬───────────────┬───────────────┬───────────────┬───────────────┬───────────────╮   ╭───────────────┬───────────────┬───────────────┬───────────────┬───────────────┬───────────────╮
	___				HRM_LT(Q,		W,				E,				R,				T)					HRM_RT(Y,		U,				I,				O,				P)				___
//├───────────────┼───────────────┼───────────────┼───────────────┼───────────────┼───────────────┤   ├───────────────┼───────────────┼───────────────┼───────────────┼───────────────┼───────────────┤
	&kp TAB			HRM_LM(A,		S,				D,				F,				G)					HRM_RM(H,		J,				K,				L,				SEMI)			&kp SQT
//├───────────────┼───────────────┼───────────────┼───────────────┼───────────────┼───────────────┤   ├───────────────┼───────────────┼───────────────┼───────────────┼───────────────┼───────────────┤
	___				HRM_LB(Z,		X,				C,				V,				B)					HRM_RB(N,		M,				COMMA,			DOT,			SLASH)			___
//╰───────────────┴───────────────┴───────────────┼───────────────┼───────────────┼───────────────┤   ├───────────────┼───────────────┼───────────────┼───────────────┴───────────────┴───────────────╯
													___				___				&mt_b FN_LBI SPACE	___				___				___
//                                                ╰───────────────┴───────────────┴───────────────╯   ╰───────────────┴───────────────┴───────────────╯
			>;
		};


/*
		enthium {
			display-name = "Enthium";
			bindings = <
//╭───────────────┬───────────────┬───────────────┬───────────────┬───────────────┬───────────────╮   ╭───────────────┬───────────────┬───────────────┬───────────────┬───────────────┬───────────────╮
	___				HRM_LT(Z,		P,				D,				L,				X)					&kp EQUAL		&kp U			&kp O			&kp Y			&kp Q			___
//├───────────────┼───────────────┼───────────────┼───────────────┼───────────────┼───────────────┤   ├───────────────┼───────────────┼───────────────┼───────────────┼───────────────┼───────────────┤
	&kp W			HRM_LM(S,		N,				T,				H,				K)					HRM_RM(MINUS,	E,				A,				I,				C)				&kp B
//├───────────────┼───────────────┼───────────────┼───────────────┼───────────────┼───────────────┤   ├───────────────┼───────────────┼───────────────┼───────────────┼───────────────┼───────────────┤
	___				HRM_LB(V,		F,				G,				M,				J)					&kp SEMICOLON	&fsbs			&kp DOT			&kp COMMA		&kp SQT			___
//╰───────────────┴───────────────┴───────────────┼───────────────┼───────────────┼───────────────┤   ├───────────────┼───────────────┼───────────────┼───────────────┴───────────────┴───────────────╯
													___				&magic_ctrl_c	&magic_r	&mt_b FN_RBI FN_RBI_BIND &lt_b FN_RB FN_RB_BIND ___
//                                                ╰───────────────┴───────────────┴───────────────╯   ╰───────────────┴───────────────┴───────────────╯
			>;
		};
*/


		navLayer {
			display-name = "Nav";
			bindings = <
//╭───────────────┬───────────────┬───────────────┬───────────────┬───────────────┬───────────────╮   ╭───────────────┬───────────────┬───────────────┬───────────────┬───────────────┬───────────────╮
	&kp BACKSPACE	&kp SPACE		&kp LG(LC(LEFT)) &mmv MOVE_UP &kp LG(LC(RIGHT))	&kp SPACE			&msc SCRL_UP	&mkp LCLK		&mkp MCLK		&mkp RCLK		&triple_click	&kp DELETE
//├───────────────┼───────────────┼───────────────┼───────────────┼───────────────┼───────────────┤   ├───────────────┼───────────────┼───────────────┼───────────────┼───────────────┼───────────────┤
	&kp LC(W)		&kp LC(LS(TAB)) &mmv MOVE_LEFT &mmv MOVE_DOWN &mmv MOVE_RIGHT	&kp LG(LS(S))		&msc SCRL_DOWN	&kp LEFT		&kp DOWN		&kp UP			&kp RIGHT		___
//├───────────────┼───────────────┼───────────────┼───────────────┼───────────────┼───────────────┤   ├───────────────┼───────────────┼───────────────┼───────────────┼───────────────┼───────────────┤
	___				&kp LC(TAB)		&kp LC(X)		&kp LC(C)	&mt_b LS(LC(V)) LC(V) &triple_click		HRM_RB(SPACE,	HOME,			PGDN,			PGUP,			END)			___
//╰───────────────┴───────────────┴───────────────┼───────────────┼───────────────┼───────────────┤   ├───────────────┼───────────────┼───────────────┼───────────────┴───────────────┴───────────────╯
													&kp ESC			___				&mt_b FN_LBI SPACE	___				___				&kp ENTER
//                                                ╰───────────────┴───────────────┴───────────────╯   ╰───────────────┴───────────────┴───────────────╯
			>;
		};


		symbols {
			display-name = "Sym";
			bindings = <
//╭───────────────┬───────────────┬───────────────┬───────────────┬───────────────┬───────────────╮   ╭───────────────┬───────────────┬───────────────┬───────────────┬───────────────┬───────────────╮
	&kp DELETE		HRM_LT(QMARK,	EXCL,			MINUS,			BSLH,			AT)					HRM_RT(HASH,	PRCNT,			PLUS,			EQUAL,			GRAVE)			&kp BACKSPACE
//├───────────────┼───────────────┼───────────────┼───────────────┼───────────────┼───────────────┤   ├───────────────┼───────────────┼───────────────┼───────────────┼───────────────┼───────────────┤
	&kp SQT			HRM_LM(LT,		LBKT,			LBRC,			RS(N9),			SEMI)				HRM_RM(COLON,	LS(N0),			RBRC,			RBKT,			GT)				&kp DQT
//├───────────────┼───────────────┼───────────────┼───────────────┼───────────────┼───────────────┤   ├───────────────┼───────────────┼───────────────┼───────────────┼───────────────┼───────────────┤
	&larr			HRM_LB(COMMA,	TILDE,			CARET,			FSLH,			UNDER)				HRM_LB(DOLLAR,	STAR,			PIPE,			AMPS,			DOT)			&rarr
//╰───────────────┴───────────────┴───────────────┼───────────────┼───────────────┼───────────────┤   ├───────────────┼───────────────┼───────────────┼───────────────┴───────────────┴───────────────╯
													___				___				&mt_b FN_LBI SPACE	___				___				___
//                                                ╰───────────────┴───────────────┴───────────────╯   ╰───────────────┴───────────────┴───────────────╯
			>;
		};


		numLayer {
			display-name = "Num";
			bindings = <
//╭───────────────┬───────────────┬───────────────┬───────────────┬───────────────┬───────────────╮   ╭───────────────┬───────────────┬───────────────┬───────────────┬───────────────┬───────────────╮
	___				&triple_zero	&kp N7			&kp N8			&kp N9			&kp LS(A)			&kp LS(D)		&kp N7			&kp N8			&kp N9			&triple_zero	___
//├───────────────┼───────────────┼───────────────┼───────────────┼───────────────┼───────────────┤   ├───────────────┼───────────────┼───────────────┼───────────────┼───────────────┼───────────────┤
	&triple_zero	HRM_LM(N0,		N4,				N5,				N6,				LS(B))				HRM_RM(LS(E),	N4,				N5,				N6,				N0)				&triple_zero
//├───────────────┼───────────────┼───────────────┼───────────────┼───────────────┼───────────────┤   ├───────────────┼───────────────┼───────────────┼───────────────┼───────────────┼───────────────┤
	___				HRM_LB(N0,		N1,				N2,				N3,				LS(C))				HRM_RB(LS(F),	N1,				N2,				N3,				N0)				___
//╰───────────────┴───────────────┴───────────────┼───────────────┼───────────────┼───────────────┤   ├───────────────┼───────────────┼───────────────┼───────────────┴───────────────┴───────────────╯
													___				___				___					___				___				___
//                                                ╰───────────────┴───────────────┴───────────────╯   ╰───────────────┴───────────────┴───────────────╯
			>;
		};


		macro {
			display-name = "Macro";
			bindings = <
//╭───────────────┬───────────────┬───────────────┬───────────────┬───────────────┬───────────────╮   ╭───────────────┬───────────────┬───────────────┬───────────────┬───────────────┬───────────────╮
	___				XXX				XXX				&hash_define	XXX				&email				&shebang		XXX				XXX				XXX				XXX				___
//├───────────────┼───────────────┼───────────────┼───────────────┼───────────────┼───────────────┤   ├───────────────┼───────────────┼───────────────┼───────────────┼───────────────┼───────────────┤
	XXX				&const_kw		&np				&m_true			XXX				XXX					XXX				XXX				XXX				&hash_include	&sizeof_kw		XXX
//├───────────────┼───────────────┼───────────────┼───────────────┼───────────────┼───────────────┤   ├───────────────┼───────────────┼───────────────┼───────────────┼───────────────┼───────────────┤
	&mo META		XXX				XXX				XXX				XXX				XXX					XXX				XXX				XXX				XXX				&m_false		&mo META
//╰───────────────┴───────────────┴───────────────┼───────────────┼───────────────┼───────────────┤   ├───────────────┼───────────────┼───────────────┼───────────────┴───────────────┴───────────────╯
													___				___				___					___				___				&to BASE
//                                                ╰───────────────┴───────────────┴───────────────╯   ╰───────────────┴───────────────┴───────────────╯
			>;
		};


		meta {
			display-name = "Meta";
			bindings = <
//╭───────────────┬───────────────┬───────────────┬───────────────┬───────────────┬───────────────╮   ╭───────────────┬───────────────┬───────────────┬───────────────┬───────────────┬───────────────╮
	&kp F1			&kp F2			&kp F3			&kp F4			&kp F5			&kp F6				&kp F7			&kp F8			&kp F9			&kp F10			&kp F11			&kp F12
//├───────────────┼───────────────┼───────────────┼───────────────┼───────────────┼───────────────┤   ├───────────────┼───────────────┼───────────────┼───────────────┼───────────────┼───────────────┤
	&clr_mod		&kt HRM_LM1		&kt HRM_LM2		&kt HRM_LM3		&kt HRM_LM4		&kt HRM_LM5			&mm_bt0			&mm_bt1			&mm_bt2			&mm_bt3			&mm_bt4			&kp LC(LA(DELETE))
//├───────────────┼───────────────┼───────────────┼───────────────┼───────────────┼───────────────┤   ├───────────────┼───────────────┼───────────────┼───────────────┼───────────────┼───────────────┤
	___				&to BASE		&to QWER		___				___				___					___				&kp C_MUTE		&kp C_VOL_DN	&kp C_VOL_UP	&kp C_PP		___
//╰───────────────┴───────────────┴───────────────┼───────────────┼───────────────┼───────────────┤   ├───────────────┼───────────────┼───────────────┼───────────────┴───────────────┴───────────────╯
													&sys_reset		&bt BT_CLR		&bootloader			&bootloader		&bt BT_CLR		&sys_reset
//                                                ╰───────────────┴───────────────┴───────────────╯   ╰───────────────┴───────────────┴───────────────╯
			>;
		};
	};
};


/*
		layerName {
			display-name = "layerName";
			bindings = <
//╭───────────────┬───────────────┬───────────────┬───────────────┬───────────────┬───────────────╮   ╭───────────────┬───────────────┬───────────────┬───────────────┬───────────────┬───────────────╮
	___				___				___				___				___				___					___				___				___				___				___				___
//├───────────────┼───────────────┼───────────────┼───────────────┼───────────────┼───────────────┤   ├───────────────┼───────────────┼───────────────┼───────────────┼───────────────┼───────────────┤
	___				___				___				___				___				___					___				___				___				___				___				___
//├───────────────┼───────────────┼───────────────┼───────────────┼───────────────┼───────────────┤   ├───────────────┼───────────────┼───────────────┼───────────────┼───────────────┼───────────────┤
	___				___				___				___				___				___					___				___				___				___				___				___
//╰───────────────┴───────────────┴───────────────┼───────────────┼───────────────┼───────────────┤   ├───────────────┼───────────────┼───────────────┼───────────────┴───────────────┴───────────────╯
													___				___				___					___				___				___
//                                                ╰───────────────┴───────────────┴───────────────╯   ╰───────────────┴───────────────┴───────────────╯
			>;
*/

